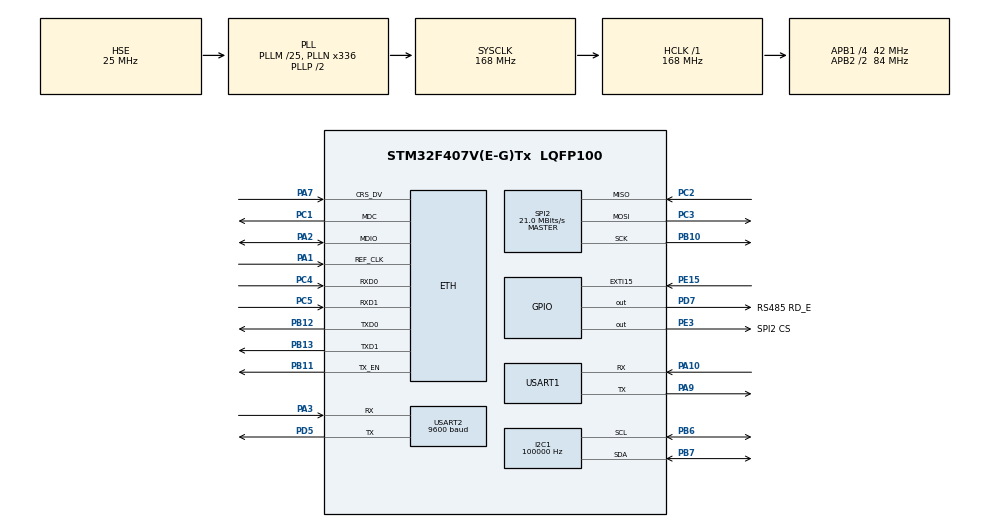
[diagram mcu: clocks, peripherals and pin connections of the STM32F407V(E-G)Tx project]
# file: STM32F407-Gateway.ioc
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ADC1.Channel-1\#ChannelRegularConversion=ADC_CHANNEL_TEMPSENSOR
ADC1.Channel-2\#ChannelRegularConversion=ADC_CHANNEL_VREFINT
ADC1.ContinuousConvMode=DISABLE
ADC1.DMAContinuousRequests=ENABLE
ADC1.EOCSelection=ADC_EOC_SEQ_CONV
ADC1.EnableAnalogWatchDog=true
ADC1.ExternalTrigConv=ADC_EXTERNALTRIGCONV_T3_TRGO
ADC1.HighThreshold=1225
ADC1.ITMode=ENABLE
ADC1.NbrOfConversion=2
ADC1.NbrOfConversionFlag=1
ADC1.Rank-1\#ChannelRegularConversion=1
ADC1.Rank-2\#ChannelRegularConversion=2
ADC1.SamplingTime-1\#ChannelRegularConversion=ADC_SAMPLETIME_144CYCLES
ADC1.SamplingTime-2\#ChannelRegularConversion=ADC_SAMPLETIME_144CYCLES
ADC1.ScanConvMode=ENABLE
ADC1.WatchdogChannel=ADC_CHANNEL_TEMPSENSOR
ADC1.master=1
Dma.ADC1.6.Direction=DMA_PERIPH_TO_MEMORY
Dma.ADC1.6.FIFOMode=DMA_FIFOMODE_DISABLE
Dma.ADC1.6.Instance=DMA2_Stream4
Dma.ADC1.6.MemDataAlignment=DMA_MDATAALIGN_HALFWORD
Dma.ADC1.6.MemInc=DMA_MINC_ENABLE
Dma.ADC1.6.Mode=DMA_CIRCULAR
Dma.ADC1.6.PeriphDataAlignment=DMA_PDATAALIGN_HALFWORD
Dma.ADC1.6.PeriphInc=DMA_PINC_DISABLE
Dma.ADC1.6.Priority=DMA_PRIORITY_MEDIUM
Dma.Request0=SPI2_RX
Dma.Request1=SPI2_TX
Dma.Request2=USART1_RX
Dma.Request3=USART1_TX
Dma.Request4=USART2_RX
Dma.Request5=USART2_TX
Dma.Request6=ADC1
Dma.SPI2_RX.0.Direction=DMA_PERIPH_TO_MEMORY
Dma.SPI2_RX.0.FIFOMode=DMA_FIFOMODE_DISABLE
Dma.SPI2_RX.0.Instance=DMA1_Stream3
Dma.SPI2_RX.0.MemDataAlignment=DMA_MDATAALIGN_BYTE
Dma.SPI2_RX.0.MemInc=DMA_MINC_ENABLE
Dma.SPI2_RX.0.Mode=DMA_NORMAL
Dma.SPI2_RX.0.PeriphDataAlignment=DMA_PDATAALIGN_BYTE
Dma.SPI2_RX.0.PeriphInc=DMA_PINC_DISABLE
Dma.SPI2_RX.0.Priority=DMA_PRIORITY_MEDIUM
Dma.SPI2_TX.1.Direction=DMA_MEMORY_TO_PERIPH
Dma.SPI2_TX.1.FIFOMode=DMA_FIFOMODE_DISABLE
Dma.SPI2_TX.1.Instance=DMA1_Stream4
Dma.SPI2_TX.1.MemDataAlignment=DMA_MDATAALIGN_BYTE
Dma.SPI2_TX.1.MemInc=DMA_MINC_ENABLE
Dma.SPI2_TX.1.Mode=DMA_NORMAL
Dma.SPI2_TX.1.PeriphDataAlignment=DMA_PDATAALIGN_BYTE
Dma.SPI2_TX.1.PeriphInc=DMA_PINC_DISABLE
Dma.SPI2_TX.1.Priority=DMA_PRIORITY_MEDIUM
Dma.USART1_RX.2.Direction=DMA_PERIPH_TO_MEMORY
Dma.USART1_RX.2.FIFOMode=DMA_FIFOMODE_DISABLE
Dma.USART1_RX.2.Instance=DMA2_Stream2
Dma.USART1_RX.2.MemDataAlignment=DMA_MDATAALIGN_BYTE
Dma.USART1_RX.2.MemInc=DMA_MINC_ENABLE
Dma.USART1_RX.2.Mode=DMA_CIRCULAR
Dma.USART1_RX.2.PeriphDataAlignment=DMA_PDATAALIGN_BYTE
Dma.USART1_RX.2.PeriphInc=DMA_PINC_DISABLE
Dma.USART1_RX.2.Priority=DMA_PRIORITY_VERY_HIGH
Dma.USART1_TX.3.Direction=DMA_MEMORY_TO_PERIPH
Dma.USART1_TX.3.FIFOMode=DMA_FIFOMODE_DISABLE
Dma.USART1_TX.3.Instance=DMA2_Stream7
Dma.USART1_TX.3.MemDataAlignment=DMA_MDATAALIGN_BYTE
Dma.USART1_TX.3.MemInc=DMA_MINC_ENABLE
Dma.USART1_TX.3.Mode=DMA_NORMAL
Dma.USART1_TX.3.PeriphDataAlignment=DMA_PDATAALIGN_BYTE
Dma.USART1_TX.3.PeriphInc=DMA_PINC_DISABLE
Dma.USART1_TX.3.Priority=DMA_PRIORITY_VERY_HIGH
Dma.USART2_RX.4.Direction=DMA_PERIPH_TO_MEMORY
Dma.USART2_RX.4.FIFOMode=DMA_FIFOMODE_DISABLE
Dma.USART2_RX.4.Instance=DMA1_Stream5
Dma.USART2_RX.4.MemDataAlignment=DMA_MDATAALIGN_BYTE
Dma.USART2_RX.4.MemInc=DMA_MINC_ENABLE
Dma.USART2_RX.4.Mode=DMA_NORMAL
Dma.USART2_RX.4.PeriphDataAlignment=DMA_PDATAALIGN_BYTE
Dma.USART2_RX.4.PeriphInc=DMA_PINC_DISABLE
Dma.USART2_RX.4.Priority=DMA_PRIORITY_VERY_HIGH
Dma.USART2_TX.5.Direction=DMA_MEMORY_TO_PERIPH
Dma.USART2_TX.5.FIFOMode=DMA_FIFOMODE_DISABLE
Dma.USART2_TX.5.Instance=DMA1_Stream6
Dma.USART2_TX.5.MemDataAlignment=DMA_MDATAALIGN_BYTE
Dma.USART2_TX.5.MemInc=DMA_MINC_ENABLE
Dma.USART2_TX.5.Mode=DMA_NORMAL
Dma.USART2_TX.5.PeriphDataAlignment=DMA_PDATAALIGN_BYTE
Dma.USART2_TX.5.PeriphInc=DMA_PINC_DISABLE
Dma.USART2_TX.5.Priority=DMA_PRIORITY_VERY_HIGH
ETH.MediaInterface=HAL_ETH_RMII_MODE
ETH.RxBuffLen=1536
ETH.RxMode=ETH_RXINTERRUPT_MODE
FREERTOS.Mutexes01=Mutex_P_R,Static,Mutex_P_RControlBlock
FREERTOS.configUSE_COUNTING_SEMAPHORES=1
FREERTOS.Queues01=Queue_DeviceData_Rx,8,356,1,Static,Queue_DeviceData_RxBuffer,Queue_DeviceData_RxControlBlock;Queue_FlashData,30,4,1,Static,Queue_FlashDataBuffer,Queue_FlashDataControlBlock;Queue_LogData,20,12,1,Static,Queue_LogDataBuffer,Queue_LogDataControlBlock;Queue_Modbus_Request,1,16,1,Static,Queue_Modbus_RequestBuffer,Queue_Modbus_RequestControlBlock;Queue_Modbus_Respond,1,76,1,Static,Queue_Modbus_RespondBuffer,Queue_Modbus_RespondControlBlock
FREERTOS.Tasks01=defaultTask,24,128,StartDefaultTask,Default,NULL,Dynamic,NULL,NULL;Task_Net,47,1024,Task_Net_Entry,Default,NULL,Static,Task_NetBuffer,Task_NetControlBlock;Task_RS232,39,128,Task_RS232_Entry,Default,NULL,Static,Task_RS232Buffer,Task_RS232ControlBlock;Task_RS485,54,128,Task_RS485_Entry,Default,NULL,Static,Task_RS485Buffer,Task_RS485ControlBlock;Task_FStorage,30,128,Task_FStorage_Entry,Default,NULL,Static,Task_FStorageBuffer,Task_FStorageControlBlock;Task_Edge,27,128,Task_Edge_Entry,Default,NULL,Static,Task_EdgeBuffer,Task_EdgeControlBlock;Task_SStorage,26,128,Task_SStorage_Entry,Default,NULL,Static,Task_SStorageBuffer,Task_SStorageControlBlock;Task_Shutdown,55,128,Task_Shutdown_Entry,Default,NULL,Static,Task_ShutdownBuffer,Task_ShutdownControlBlock;Task_Pollin,24,128,Task_Pollin_Entry,Default,NULL,Static,Task_PollinBuffer,Task_PollinControlBlock
I2C1.ClockSpeed=100000
I2C1.I2C_Mode=I2C_Fast
LWIP.GATEWAY_ADDRESS=192.168.001.001
LWIP.IP_ADDRESS=192.168.100.253
LWIP.LWIP_DHCP=0
LWIP.NETMASK_ADDRESS=255.255.255.000
LWIP.Version=v2.1.2_Cube
Mcu.Family=STM32F4
Mcu.Name=STM32F407V(E-G)Tx
Mcu.Package=LQFP100
NVIC.DMA1_Stream3_IRQn=true\:5\:0\:false\:false\:true\:true\:false\:true\:true
NVIC.DMA1_Stream4_IRQn=true\:5\:0\:false\:false\:true\:true\:false\:true\:true
NVIC.DMA1_Stream5_IRQn=true\:5\:0\:false\:false\:true\:true\:false\:true\:true
NVIC.DMA1_Stream6_IRQn=true\:5\:0\:false\:false\:true\:true\:false\:true\:true
NVIC.DMA2_Stream2_IRQn=true\:5\:0\:false\:false\:true\:true\:false\:true\:true
NVIC.DMA2_Stream4_IRQn=true\:5\:0\:false\:false\:true\:true\:false\:true\:true
NVIC.DMA2_Stream7_IRQn=true\:5\:0\:false\:false\:true\:true\:false\:true\:true
NVIC.ETH_IRQn=true\:5\:0\:false\:false\:true\:true\:false\:true\:true
NVIC.PriorityGroup=NVIC_PRIORITYGROUP_4
NVIC.TIM3_IRQn=true\:5\:0\:false\:false\:true\:true\:false\:true\:true
NVIC.USART2_IRQn=true\:5\:0\:false\:false\:true\:true\:false\:true\:true
PA1.Mode=RMII
PA1.Signal=ETH_REF_CLK
PA10.Mode=Asynchronous
PA10.Signal=USART1_RX
PA2.Mode=RMII
PA2.Signal=ETH_MDIO
PA3.Mode=Asynchronous
PA3.Signal=USART2_RX
PA7.Mode=RMII
PA7.Signal=ETH_CRS_DV
PA9.Mode=Asynchronous
PA9.Signal=USART1_TX
PB10.Mode=Full_Duplex_Master
PB10.Signal=SPI2_SCK
PB11.Mode=RMII
PB11.Signal=ETH_TX_EN
PB12.Mode=RMII
PB12.Signal=ETH_TXD0
PB13.Mode=RMII
PB13.Signal=ETH_TXD1
PB6.Mode=I2C
PB6.Signal=I2C1_SCL
PB7.Mode=I2C
PB7.Signal=I2C1_SDA
PC1.Mode=RMII
PC1.Signal=ETH_MDC
PC14-OSC32_IN.Mode=LSE-External-Oscillator
PC14-OSC32_IN.Signal=RCC_OSC32_IN
PC15-OSC32_OUT.Mode=LSE-External-Oscillator
PC15-OSC32_OUT.Signal=RCC_OSC32_OUT
PC2.Mode=Full_Duplex_Master
PC2.Signal=SPI2_MISO
PC3.Mode=Full_Duplex_Master
PC3.Signal=SPI2_MOSI
PC4.Mode=RMII
PC4.Signal=ETH_RXD0
PC5.Mode=RMII
PC5.Signal=ETH_RXD1
PD5.Mode=Asynchronous
PD5.Signal=USART2_TX
PD7.GPIO_Label=RS485 RD_E
PD7.GPIO_ModeDefaultOutputPP=GPIO_MODE_OUTPUT_PP
PD7.Signal=GPIO_Output
PE15.Signal=GPXTI15
PE3.GPIO_Label=SPI2 CS
PE3.GPIO_ModeDefaultOutputPP=GPIO_MODE_OUTPUT_PP
PE3.GPIO_PuPd=GPIO_NOPULL
PE3.GPIO_Speed=GPIO_SPEED_FREQ_VERY_HIGH
PE3.PinState=GPIO_PIN_SET
PE3.Signal=GPIO_Output
PH0-OSC_IN.Mode=HSE-External-Oscillator
PH0-OSC_IN.Signal=RCC_OSC_IN
PH1-OSC_OUT.Mode=HSE-External-Oscillator
PH1-OSC_OUT.Signal=RCC_OSC_OUT
ProjectManager.HeapSize=0x200
ProjectManager.StackSize=0x400
ProjectManager.TargetToolchain=MDK-ARM V5.32
RCC.48MHZClocksFreq_Value=84000000
RCC.AHBFreq_Value=168000000
RCC.APB1CLKDivider=RCC_HCLK_DIV4
RCC.APB1Freq_Value=42000000
RCC.APB1TimFreq_Value=84000000
RCC.APB2CLKDivider=RCC_HCLK_DIV2
RCC.APB2Freq_Value=84000000
RCC.APB2TimFreq_Value=168000000
RCC.CortexFreq_Value=168000000
RCC.HCLKFreq_Value=168000000
RCC.HSE_VALUE=25000000
RCC.HSI_VALUE=16000000
RCC.PLLM=25
RCC.PLLN=336
RCC.PLLSourceVirtual=RCC_PLLSOURCE_HSE
RCC.RCC_RTC_Clock_Source=RCC_RTCCLKSOURCE_LSE
RCC.RCC_RTC_Clock_SourceVirtual=RCC_RTCCLKSOURCE_LSE
RCC.SYSCLKFreq_VALUE=168000000
RCC.SYSCLKSource=RCC_SYSCLKSOURCE_PLLCLK
RCC.VCOOutputFreq_Value=336000000
RTC.Format=RTC_FORMAT_BCD
RTC.Year=26
SPI2.BaudRatePrescaler=SPI_BAUDRATEPRESCALER_2
SPI2.CalculateBaudRate=21.0 MBits/s
SPI2.Direction=SPI_DIRECTION_2LINES
SPI2.Mode=SPI_MODE_MASTER
SPI2.VirtualType=VM_MASTER
TIM3.AutoReloadPreload=TIM_AUTORELOAD_PRELOAD_ENABLE
TIM3.Period=9999
TIM3.Prescaler=8399
TIM3.TIM_MasterOutputTrigger=TIM_TRGO_UPDATE
USART1.VirtualMode=VM_ASYNC
USART2.BaudRate=9600
USART2.VirtualMode=VM_ASYNC
VP_ADC1_TempSens_Input.Mode=IN-TempSens
VP_ADC1_Vref_Input.Mode=IN-Vrefint
VP_FREERTOS_VS_CMSIS_V2.Mode=CMSIS_V2
VP_IWDG_VS_IWDG.Mode=IWDG_Activate
VP_LWIP_VS_Enabled.Mode=Enabled
VP_RTC_VS_RTC_Activate.Mode=RTC_Enabled
VP_RTC_VS_RTC_Calendar.Mode=RTC_Calendar
VP_TIM3_VS_ClockSourceINT.Mode=Internal
board=custom

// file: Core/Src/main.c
/* USER CODE BEGIN Header */
/**
  ******************************************************************************
  * @file           : main.c
  * @brief          : Main program body
  ******************************************************************************
  * @attention
  *
  * Copyright (c) 2026 STMicroelectronics.
  * All rights reserved.
  *
  * This software is licensed under terms that can be found in the LICENSE file
  * in the root directory of this software component.
  * If no LICENSE file comes with this software, it is provided AS-IS.
  *
  ******************************************************************************
  */
/* USER CODE END Header */
#include "main.h"
#include "cmsis_os.h"
#include "adc.h"
#include "dma.h"
#include "i2c.h"
#include "iwdg.h"
#include "lwip.h"
#include "rtc.h"
#include "spi.h"
#include "tim.h"
#include "usart.h"
#include "gpio.h"

/* USER CODE BEGIN Includes */
#include "app_message.h"
#include "app_tasks.h"
/* USER CODE END Includes */

/* USER CODE BEGIN PV */
volatile uint32_t TimeStamp = 0U;
/* USER CODE END PV */

void SystemClock_Config(void);
void MX_FREERTOS_Init(void);

int main(void)
{

  /* MCU Configuration--------------------------------------------------------*/

  /* Reset of all peripherals, Initializes the Flash interface and the Systick. */
  HAL_Init();

  /* Configure the system clock */
  SystemClock_Config();

  /* Initialize all configured peripherals */
  MX_GPIO_Init();
  MX_DMA_Init();
  MX_I2C1_Init();
  MX_SPI2_Init();
  MX_USART1_UART_Init();
  MX_USART2_UART_Init();
  MX_IWDG_Init();
  MX_ADC1_Init();
  MX_RTC_Init();
  MX_TIM3_Init();
  /* USER CODE BEGIN 2 */
  TimeStamp = Timestamp_Init(); //初始化当前时间戳，单位为秒，UTC

  if (Time3_Start() == 0U) //启动TIM3，独立维护TimeStamp
  {
    Error_Handler();
  }

  /* USER CODE END 2 */

  /* Init scheduler */
  osKernelInitialize();

  /* Call init function for freertos objects (in cmsis_os2.c) */
  MX_FREERTOS_Init();

  /* Start scheduler */
  osKernelStart();

  /* We should never get here as control is now taken by the scheduler */

  /* Infinite loop */
  while (1)
  {

  }
}

void SystemClock_Config(void)
{
  RCC_OscInitTypeDef RCC_OscInitStruct = {0};
  RCC_ClkInitTypeDef RCC_ClkInitStruct = {0};

  /** Configure the main internal regulator output voltage
  */
  __HAL_RCC_PWR_CLK_ENABLE();
  __HAL_PWR_VOLTAGESCALING_CONFIG(PWR_REGULATOR_VOLTAGE_SCALE1);

  /** Initializes the RCC Oscillators according to the specified parameters
  * in the RCC_OscInitTypeDef structure.
  */
  RCC_OscInitStruct.OscillatorType = RCC_OSCILLATORTYPE_LSI|RCC_OSCILLATORTYPE_HSE
                              |RCC_OSCILLATORTYPE_LSE;
  RCC_OscInitStruct.HSEState = RCC_HSE_ON;
  RCC_OscInitStruct.LSEState = RCC_LSE_ON;
  RCC_OscInitStruct.LSIState = RCC_LSI_ON;
  RCC_OscInitStruct.PLL.PLLState = RCC_PLL_ON;
  RCC_OscInitStruct.PLL.PLLSource = RCC_PLLSOURCE_HSE;
  RCC_OscInitStruct.PLL.PLLM = 25;
  RCC_OscInitStruct.PLL.PLLN = 336;
  RCC_OscInitStruct.PLL.PLLP = RCC_PLLP_DIV2;
  RCC_OscInitStruct.PLL.PLLQ = 4;
  if (HAL_RCC_OscConfig(&RCC_OscInitStruct) != HAL_OK)
  {
    Error_Handler();
  }

  /** Initializes the CPU, AHB and APB buses clocks
  */
  RCC_ClkInitStruct.ClockType = RCC_CLOCKTYPE_HCLK|RCC_CLOCKTYPE_SYSCLK
                              |RCC_CLOCKTYPE_PCLK1|RCC_CLOCKTYPE_PCLK2;
  RCC_ClkInitStruct.SYSCLKSource = RCC_SYSCLKSOURCE_PLLCLK;
  RCC_ClkInitStruct.AHBCLKDivider = RCC_SYSCLK_DIV1;
  RCC_ClkInitStruct.APB1CLKDivider = RCC_HCLK_DIV4;
  RCC_ClkInitStruct.APB2CLKDivider = RCC_HCLK_DIV2;

  if (HAL_RCC_ClockConfig(&RCC_ClkInitStruct, FLASH_LATENCY_5) != HAL_OK)
  {
    Error_Handler();
  }
}

void Error_Handler(void)
{
  __disable_irq();
  while (1)
  {
  }
}

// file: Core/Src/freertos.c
/* USER CODE BEGIN Header */
/**
  ******************************************************************************
  * File Name          : freertos.c
  * Description        : Code for freertos applications
  ******************************************************************************
  * @attention
  *
  * Copyright (c) 2026 STMicroelectronics.
  * All rights reserved.
  *
  * This software is licensed under terms that can be found in the LICENSE file
  * in the root directory of this software component.
  * If no LICENSE file comes with this software, it is provided AS-IS.
  *
  ******************************************************************************
  */
/* USER CODE END Header */

#include "FreeRTOS.h"
#include "task.h"
#include "main.h"
#include "cmsis_os.h"

/* USER CODE BEGIN Includes */
#include "app_tasks.h"
/* USER CODE END Includes */

typedef StaticTask_t osStaticThreadDef_t;
typedef StaticQueue_t osStaticMessageQDef_t;
typedef StaticSemaphore_t osStaticMutexDef_t;
typedef StaticSemaphore_t osStaticSemaphoreDef_t;

/* Definitions for defaultTask */
osThreadId_t defaultTaskHandle;
const osThreadAttr_t defaultTask_attributes = {
  .name = "defaultTask",
  .stack_size = 128 * 4,
  .priority = (osPriority_t) osPriorityNormal,
};
/* Definitions for Task_Net */
osThreadId_t Task_NetHandle;
uint32_t Task_NetBuffer[ 1024 ];
osStaticThreadDef_t Task_NetControlBlock;
const osThreadAttr_t Task_Net_attributes = {
  .name = "Task_Net",
  .cb_mem = &Task_NetControlBlock,
  .cb_size = sizeof(Task_NetControlBlock),
  .stack_mem = &Task_NetBuffer[0],
  .stack_size = sizeof(Task_NetBuffer),
  .priority = (osPriority_t) osPriorityHigh7,
};
/* Definitions for Task_RS232 */
osThreadId_t Task_RS232Handle;
uint32_t Task_RS232Buffer[ 128 ];
osStaticThreadDef_t Task_RS232ControlBlock;
const osThreadAttr_t Task_RS232_attributes = {
  .name = "Task_RS232",
  .cb_mem = &Task_RS232ControlBlock,
  .cb_size = sizeof(Task_RS232ControlBlock),
  .stack_mem = &Task_RS232Buffer[0],
  .stack_size = sizeof(Task_RS232Buffer),
  .priority = (osPriority_t) osPriorityAboveNormal7,
};
/* Definitions for Task_RS485 */
osThreadId_t Task_RS485Handle;
uint32_t Task_RS485Buffer[ 128 ];
osStaticThreadDef_t Task_RS485ControlBlock;
const osThreadAttr_t Task_RS485_attributes = {
  .name = "Task_RS485",
  .cb_mem = &Task_RS485ControlBlock,
  .cb_size = sizeof(Task_RS485ControlBlock),
  .stack_mem = &Task_RS485Buffer[0],
  .stack_size = sizeof(Task_RS485Buffer),
  .priority = (osPriority_t) osPriorityRealtime6,
};
/* Definitions for Task_FStorage */
osThreadId_t Task_FStorageHandle;
uint32_t Task_FStorageBuffer[ 128 ];
osStaticThreadDef_t Task_FStorageControlBlock;
const osThreadAttr_t Task_FStorage_attributes = {
  .name = "Task_FStorage",
  .cb_mem = &Task_FStorageControlBlock,
  .cb_size = sizeof(Task_FStorageControlBlock),
  .stack_mem = &Task_FStorageBuffer[0],
  .stack_size = sizeof(Task_FStorageBuffer),
  .priority = (osPriority_t) osPriorityNormal6,
};
/* Definitions for Task_Edge */
osThreadId_t Task_EdgeHandle;
uint32_t Task_EdgeBuffer[ 128 ];
osStaticThreadDef_t Task_EdgeControlBlock;
const osThreadAttr_t Task_Edge_attributes = {
  .name = "Task_Edge",
  .cb_mem = &Task_EdgeControlBlock,
  .cb_size = sizeof(Task_EdgeControlBlock),
  .stack_mem = &Task_EdgeBuffer[0],
  .stack_size = sizeof(Task_EdgeBuffer),
  .priority = (osPriority_t) osPriorityNormal3,
};
/* Definitions for Task_SStorage */
osThreadId_t Task_SStorageHandle;
uint32_t Task_SStorageBuffer[ 128 ];
osStaticThreadDef_t Task_SStorageControlBlock;
const osThreadAttr_t Task_SStorage_attributes = {
  .name = "Task_SStorage",
  .cb_mem = &Task_SStorageControlBlock,
  .cb_size = sizeof(Task_SStorageControlBlock),
  .stack_mem = &Task_SStorageBuffer[0],
  .stack_size = sizeof(Task_SStorageBuffer),
  .priority = (osPriority_t) osPriorityNormal2,
};
/* Definitions for Task_Shutdown */
osThreadId_t Task_ShutdownHandle;
uint32_t Task_ShutdownBuffer[ 128 ];
osStaticThreadDef_t Task_ShutdownControlBlock;
const osThreadAttr_t Task_Shutdown_attributes = {
  .name = "Task_Shutdown",
  .cb_mem = &Task_ShutdownControlBlock,
  .cb_size = sizeof(Task_ShutdownControlBlock),
  .stack_mem = &Task_ShutdownBuffer[0],
  .stack_size = sizeof(Task_ShutdownBuffer),
  .priority = (osPriority_t) osPriorityRealtime7,
};
/* Definitions for Task_Pollin */
osThreadId_t Task_PollinHandle;
uint32_t Task_PollinBuffer[ 128 ];
osStaticThreadDef_t Task_PollinControlBlock;
const osThreadAttr_t Task_Pollin_attributes = {
  .name = "Task_Pollin",
  .cb_mem = &Task_PollinControlBlock,
  .cb_size = sizeof(Task_PollinControlBlock),
  .stack_mem = &Task_PollinBuffer[0],
  .stack_size = sizeof(Task_PollinBuffer),
  .priority = (osPriority_t) osPriorityNormal,
};
/* Definitions for Queue_DeviceData_Rx */
osMessageQueueId_t Queue_DeviceData_RxHandle;
uint8_t Queue_DeviceData_RxBuffer[ 8 * 356 ];
osStaticMessageQDef_t Queue_DeviceData_RxControlBlock;
const osMessageQueueAttr_t Queue_DeviceData_Rx_attributes = {
  .name = "Queue_DeviceData_Rx",
  .cb_mem = &Queue_DeviceData_RxControlBlock,
  .cb_size = sizeof(Queue_DeviceData_RxControlBlock),
  .mq_mem = &Queue_DeviceData_RxBuffer,
  .mq_size = sizeof(Queue_DeviceData_RxBuffer)
};
/* Definitions for Queue_FlashData */
osMessageQueueId_t Queue_FlashDataHandle;
uint8_t Queue_FlashDataBuffer[ 30 * 4 ];
osStaticMessageQDef_t Queue_FlashDataControlBlock;
const osMessageQueueAttr_t Queue_FlashData_attributes = {
  .name = "Queue_FlashData",
  .cb_mem = &Queue_FlashDataControlBlock,
  .cb_size = sizeof(Queue_FlashDataControlBlock),
  .mq_mem = &Queue_FlashDataBuffer,
  .mq_size = sizeof(Queue_FlashDataBuffer)
};
/* Definitions for Queue_LogData */
osMessageQueueId_t Queue_LogDataHandle;
uint8_t Queue_LogDataBuffer[ 20 * 12 ];
osStaticMessageQDef_t Queue_LogDataControlBlock;
const osMessageQueueAttr_t Queue_LogData_attributes = {
  .name = "Queue_LogData",
  .cb_mem = &Queue_LogDataControlBlock,
  .cb_size = sizeof(Queue_LogDataControlBlock),
  .mq_mem = &Queue_LogDataBuffer,
  .mq_size = sizeof(Queue_LogDataBuffer)
};
/* Definitions for Queue_Modbus_Request */
osMessageQueueId_t Queue_Modbus_RequestHandle;
uint8_t Queue_Modbus_RequestBuffer[ 1 * 16 ];
osStaticMessageQDef_t Queue_Modbus_RequestControlBlock;
const osMessageQueueAttr_t Queue_Modbus_Request_attributes = {
  .name = "Queue_Modbus_Request",
  .cb_mem = &Queue_Modbus_RequestControlBlock,
  .cb_size = sizeof(Queue_Modbus_RequestControlBlock),
  .mq_mem = &Queue_Modbus_RequestBuffer,
  .mq_size = sizeof(Queue_Modbus_RequestBuffer)
};
/* Definitions for Queue_Modbus_Respond */
osMessageQueueId_t Queue_Modbus_RespondHandle;
uint8_t Queue_Modbus_RespondBuffer[ 1 * 76 ];
osStaticMessageQDef_t Queue_Modbus_RespondControlBlock;
const osMessageQueueAttr_t Queue_Modbus_Respond_attributes = {
  .name = "Queue_Modbus_Respond",
  .cb_mem = &Queue_Modbus_RespondControlBlock,
  .cb_size = sizeof(Queue_Modbus_RespondControlBlock),
  .mq_mem = &Queue_Modbus_RespondBuffer,
  .mq_size = sizeof(Queue_Modbus_RespondBuffer)
};
/* Definitions for Mutex_P_R */
osMutexId_t Mutex_P_RHandle;
osStaticMutexDef_t Mutex_P_RControlBlock;
const osMutexAttr_t Mutex_P_R_attributes = {
  .name = "Mutex_P_R",
  .cb_mem = &Mutex_P_RControlBlock,
  .cb_size = sizeof(Mutex_P_RControlBlock),
};

void StartDefaultTask(void *argument);
void Task_Net_Entry(void *argument);
void Task_RS232_Entry(void *argument);
void Task_RS485_Entry(void *argument);
void Task_FStorage_Entry(void *argument);
void Task_Edge_Entry(void *argument);
void Task_SStorage_Entry(void *argument);
void Task_Shutdown_Entry(void *argument);
void Task_Pollin_Entry(void *argument);

extern void MX_LWIP_Init(void);
void MX_FREERTOS_Init(void); /* (MISRA C 2004 rule 8.1) */

void MX_FREERTOS_Init(void) {
  /* creation of Mutex_P_R */
  Mutex_P_RHandle = osMutexNew(&Mutex_P_R_attributes);

  /* Create the mutex(es) */

  /* Create the semaphore(s) */

  /* Create the queue(s) */
  /* creation of Queue_DeviceData_Rx */
  Queue_DeviceData_RxHandle = osMessageQueueNew (8, 356, &Queue_DeviceData_Rx_attributes);

  /* creation of Queue_FlashData */
  Queue_FlashDataHandle = osMessageQueueNew (30, 4, &Queue_FlashData_attributes);

  /* creation of Queue_LogData */
  Queue_LogDataHandle = osMessageQueueNew (20, 12, &Queue_LogData_attributes);

  /* creation of Queue_Modbus_Request */
  Queue_Modbus_RequestHandle = osMessageQueueNew (1, 16, &Queue_Modbus_Request_attributes);

  /* creation of Queue_Modbus_Respond */
  Queue_Modbus_RespondHandle = osMessageQueueNew (1, 76, &Queue_Modbus_Respond_attributes);

  /* Create the thread(s) */
  /* creation of defaultTask */
  defaultTaskHandle = osThreadNew(StartDefaultTask, NULL, &defaultTask_attributes);

  /* creation of Task_Net */
  Task_NetHandle = osThreadNew(Task_Net_Entry, NULL, &Task_Net_attributes);

  /* creation of Task_RS232 */
  Task_RS232Handle = osThreadNew(Task_RS232_Entry, NULL, &Task_RS232_attributes);

  /* creation of Task_RS485 */
  Task_RS485Handle = osThreadNew(Task_RS485_Entry, NULL, &Task_RS485_attributes);

  /* creation of Task_FStorage */
  Task_FStorageHandle = osThreadNew(Task_FStorage_Entry, NULL, &Task_FStorage_attributes);

  /* creation of Task_Edge */
  Task_EdgeHandle = osThreadNew(Task_Edge_Entry, NULL, &Task_Edge_attributes);

  /* creation of Task_SStorage */
  Task_SStorageHandle = osThreadNew(Task_SStorage_Entry, NULL, &Task_SStorage_attributes);

  /* creation of Task_Shutdown */
  Task_ShutdownHandle = osThreadNew(Task_Shutdown_Entry, NULL, &Task_Shutdown_attributes);

  /* creation of Task_Pollin */
  Task_PollinHandle = osThreadNew(Task_Pollin_Entry, NULL, &Task_Pollin_attributes);

}

void StartDefaultTask(void *argument)
{
  /* init code for LWIP */
  MX_LWIP_Init();
  for(;;)
  {
    osDelay(1);
  }
}

void Task_Net_Entry(void *argument)
{
  /* USER CODE BEGIN Task_Net_Entry */
  Task_Net_Run(argument);
  /* USER CODE END Task_Net_Entry */
}

void Task_RS232_Entry(void *argument)
{
  for(;;)
  {
    osDelay(1);
  }
}

void Task_RS485_Entry(void *argument)
{
  /* USER CODE BEGIN Task_RS485_Entry */
  Task_RS485_Run(argument);
  /* USER CODE END Task_RS485_Entry */
}

void Task_FStorage_Entry(void *argument)
{
  for(;;)
  {
    osDelay(1);
  }
}

void Task_Edge_Entry(void *argument)
{
  /* USER CODE BEGIN Task_Edge_Entry */
  Task_Edge_Run(argument);
  /* USER CODE END Task_Edge_Entry */
}

void Task_SStorage_Entry(void *argument)
{
  for(;;)
  {
    osDelay(1);
  }
}

void Task_Shutdown_Entry(void *argument)
{
  for(;;)
  {
    osDelay(1);
  }
}

void Task_Pollin_Entry(void *argument)
{
  /* USER CODE BEGIN Task_Pollin_Entry */
  Task_Pollin_Run(argument);
  /* USER CODE END Task_Pollin_Entry */
}
